# MDR32FG16S1QI register map
Vendor: Milandr; File version: 1.0
CPU: CM3 r1p1, little endian, MPU, no FPU, 3 interrupt priority bits
Registers are 32-bit, read-write, reset 0x0 unless marked. A register's access mark holds for its fields unless they carry their own. Offsets are from the block's base; [hi:lo] are bit positions; 'fields as' and 'values as' point back to an identical list.

## MDR_EEPROM — Flash programm memory interface controller registers
Base 0x40018000
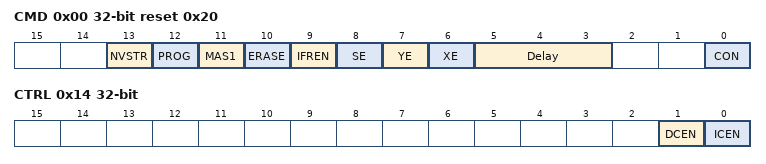
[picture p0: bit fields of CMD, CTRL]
0x00 CMD reset 0x20 — EEPROM Command Register
  [13] NVSTR, [12] PROG, [11] MAS1, [10] ERASE, [9] IFREN, [8] SE, [7] YE, [6] XE, [5:3] Delay, [0] CON
0x04 ADR — EEPROM Address Register
0x08 DI — EEPROM Read Data Register
  [31:0] DATA
0x0C DO — EEPROM Write Data Register
  [31:0] DATA
0x10 KEY — EEPROM Key Register
0x14 CTRL — EEPROM Ctrl Register
  [1] DCEN, [0] ICEN

## MDR_RST_CLK — RST_CLK
Base 0x40020000
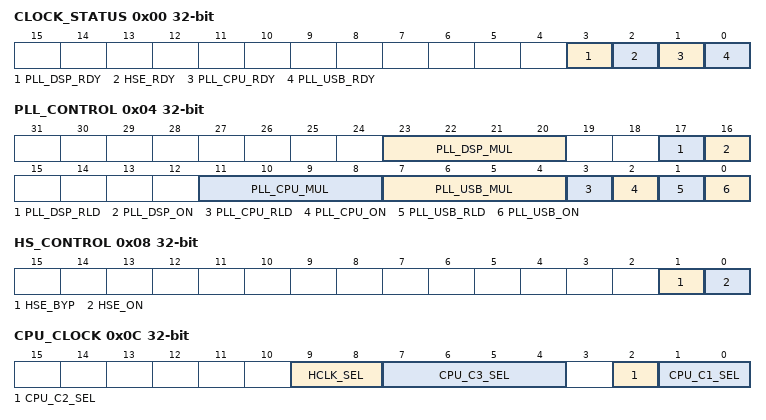
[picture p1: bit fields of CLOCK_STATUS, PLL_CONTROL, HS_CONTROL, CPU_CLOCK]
0x00 CLOCK_STATUS ro
  [3] PLL_DSP_RDY, [2] HSE_RDY, [1] PLL_CPU_RDY, [0] PLL_USB_RDY
0x04 PLL_CONTROL
  [23:20] PLL_DSP_MUL, [17] PLL_DSP_RLD, [16] PLL_DSP_ON, [11:8] PLL_CPU_MUL, [7:4] PLL_USB_MUL, [3] PLL_CPU_RLD, [2] PLL_CPU_ON, [1] PLL_USB_RLD, [0] PLL_USB_ON
0x08 HS_CONTROL
  [1] HSE_BYP, [0] HSE_ON
0x0C CPU_CLOCK
  [9:8] HCLK_SEL
    0=HSI (HSI selected); 1=CPU_C3 (CPU_C3 selected); 2=LSE (LSE selected); 3=LSI (LSI selected)
  [7:4] CPU_C3_SEL
  [2] CPU_C2_SEL
    0=CPU_C1 (CPU_C1 selected); 1=PLLCPUo selected
  [1:0] CPU_C1_SEL
    0=HSI (HSI selected); 1=HSI/2 (HSI/2 selected); 2=HSE (HSE selected); 3=HSE/2 (HSE/2 selected)
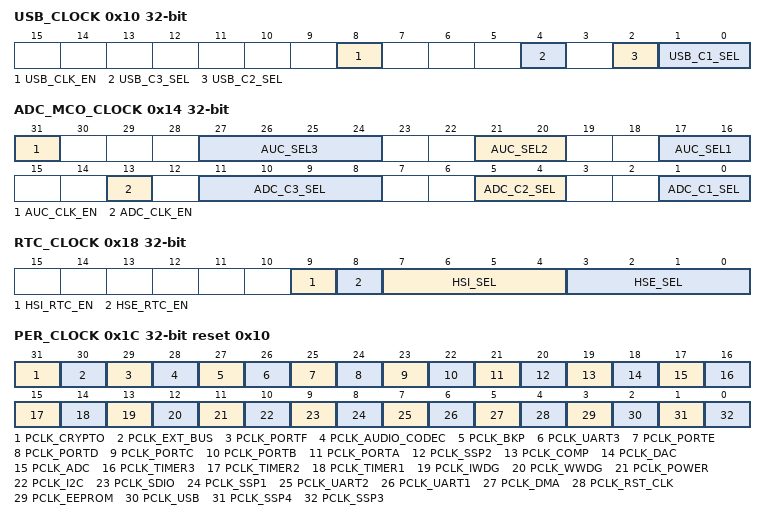
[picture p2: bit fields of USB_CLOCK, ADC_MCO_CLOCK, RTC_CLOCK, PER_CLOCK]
0x10 USB_CLOCK
  [8] USB_CLK_EN
  [4] USB_C3_SEL
    0=USB_C2 (USB_C2 selected); 1=USB_C2/2 (USB_C2/2 selected)
  [2] USB_C2_SEL
    0=USB_C1 (USB_C1 selected); 1=PLLUSBo selected
  [1:0] USB_C1_SEL
    values as CPU_CLOCK.CPU_C1_SEL
0x14 ADC_MCO_CLOCK — ADC Clock Register
  [31] AUC_CLK_EN
  [27:24] AUC_SEL3
  [21:20] AUC_SEL2
    0=AUC_C1 (AUC_C1 selected); 1=CPU_C2 (CPU_C2 selected); 2=USB_C2 (USB_C2 selected); 3=DSP_C2 (DSP_C2 selected)
  [17:16] AUC_SEL1
    values as CPU_CLOCK.CPU_C1_SEL
  [13] ADC_CLK_EN
  [11:8] ADC_C3_SEL
  [5:4] ADC_C2_SEL
    0=LSE (LSE selected); 1=LSI (LSI selected); 2=ADC_C1 (ADC_C1 selected); 3=HSI_C1 (HSI_C1 selected)
  [1:0] ADC_C1_SEL
    0=CPU_C1 (CPU_C1 selected); 1=USB_C1 (USB_C1 selected); 2=CPU_C2 (CPU_C2 selected); 3=USB_C2 (USB_C2 selected)
0x18 RTC_CLOCK
  [9] HSI_RTC_EN, [8] HSE_RTC_EN, [7:4] HSI_SEL, [3:0] HSE_SEL
0x1C PER_CLOCK reset 0x10 — Peripheral Clock Enable Register
  [31] PCLK_CRYPTO, [30] PCLK_EXT_BUS, [29] PCLK_PORTF, [28] PCLK_AUDIO_CODEC, [27] PCLK_BKP, [26] PCLK_UART3, [25] PCLK_PORTE, [24] PCLK_PORTD, [23] PCLK_PORTC, [22] PCLK_PORTB, [21] PCLK_PORTA, [20] PCLK_SSP2, [19] PCLK_COMP, [18] PCLK_DAC, [17] PCLK_ADC, [16] PCLK_TIMER3, [15] PCLK_TIMER2, [14] PCLK_TIMER1, [13] PCLK_IWDG, [12] PCLK_WWDG, [11] PCLK_POWER, [10] PCLK_I2C, [9] PCLK_SDIO, [8] PCLK_SSP1, [7] PCLK_UART2, [6] PCLK_UART1, [5] PCLK_DMA, [4] PCLK_RST_CLK, [3] PCLK_EEPROM, [2] PCLK_USB, [1] PCLK_SSP4, [0] PCLK_SSP3
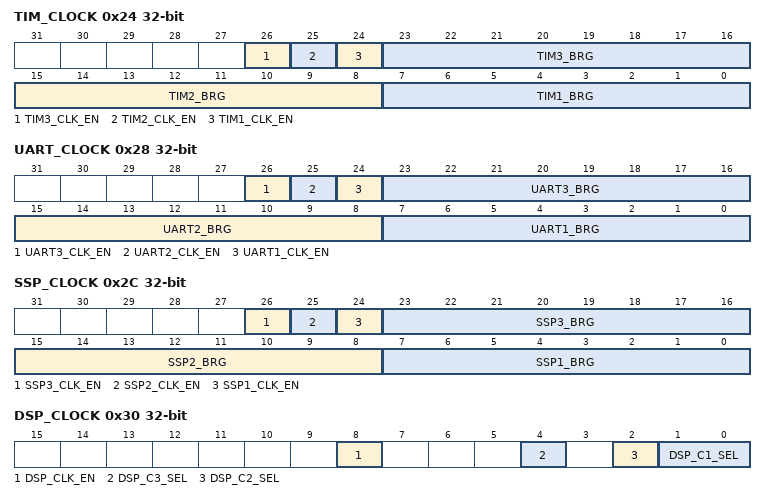
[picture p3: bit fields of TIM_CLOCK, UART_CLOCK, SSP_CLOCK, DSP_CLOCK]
0x24 TIM_CLOCK — Timer Clock Register
  [26] TIM3_CLK_EN, [25] TIM2_CLK_EN, [24] TIM1_CLK_EN, [23:16] TIM3_BRG, [15:8] TIM2_BRG, [7:0] TIM1_BRG
0x28 UART_CLOCK
  [26] UART3_CLK_EN, [25] UART2_CLK_EN, [24] UART1_CLK_EN, [23:16] UART3_BRG, [15:8] UART2_BRG, [7:0] UART1_BRG
0x2C SSP_CLOCK
  [26] SSP3_CLK_EN, [25] SSP2_CLK_EN, [24] SSP1_CLK_EN, [23:16] SSP3_BRG, [15:8] SSP2_BRG, [7:0] SSP1_BRG
0x30 DSP_CLOCK
  [8] DSP_CLK_EN
  [4] DSP_C3_SEL
  [2] DSP_C2_SEL
    0=DSP_C1 (DSP_C1 selected); 1=PLLDSPo selected
  [1:0] DSP_C1_SEL
    values as CPU_CLOCK.CPU_C1_SEL
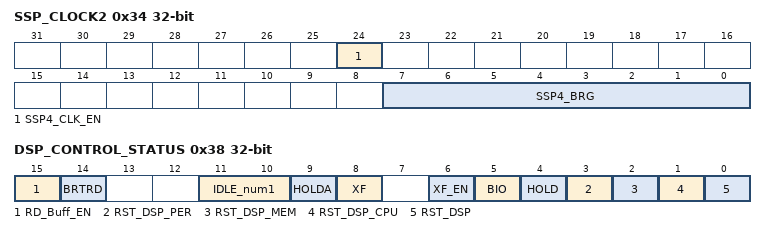
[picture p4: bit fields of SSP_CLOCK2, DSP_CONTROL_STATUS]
0x34 SSP_CLOCK2
  [24] SSP4_CLK_EN, [7:0] SSP4_BRG
0x38 DSP_CONTROL_STATUS
  [15] RD_Buff_EN, [14] BRTRD, [11:10] IDLE_num1, [9] HOLDA, [8] XF, [6] XF_EN, [5] BIO, [4] HOLD, [3] RST_DSP_PER, [2] RST_DSP_MEM, [1] RST_DSP_CPU, [0] RST_DSP

## MDR_DMA — DMA controller registers
Base 0x40028000
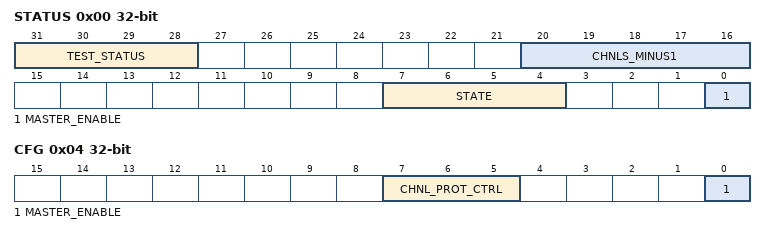
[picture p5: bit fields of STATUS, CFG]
0x00 STATUS — DMA Status Register
  [31:28] TEST_STATUS, [20:16] CHNLS_MINUS1, [7:4] STATE, [0] MASTER_ENABLE
0x04 CFG — DMA Configuration Register
  [7:5] CHNL_PROT_CTRL, [0] MASTER_ENABLE
0x08 CTRL_BASE_PTR
0x0C ALT_CTRL_BASE_PTR
0x10 WAITONREQ_STATUS
0x14 CHNL_SW_REQUEST
0x18 CHNL_USEBURST_SET
0x1C CHNL_USEBURST_CLR
0x20 CHNL_REQ_MASK_SET
0x24 CHNL_REQ_MASK_CLR
0x28 CHNL_ENABLE_SET
0x2C CHNL_ENABLE_CLR
0x30 CHNL_PRI_ALT_SET
0x34 CHNL_PRI_ALT_CLR
0x38 CHNL_PRIORITY_SET
0x3C CHNL_PRIORITY_CLR
0x4C ERR_CLR
  [0] ERR_CLR

## MDR_DMA_DSP — DMA controller registers
Base 0x300000C0
Registers as MDR_DMA, without ERR_CLR.
